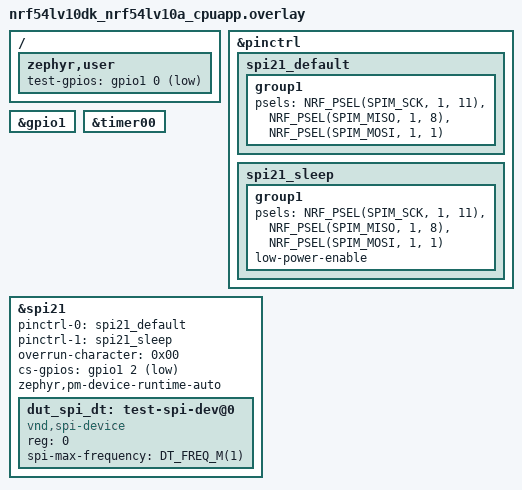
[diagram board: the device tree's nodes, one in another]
/*
 * Copyright (c) 2025 Nordic Semiconductor ASA
 *
 * SPDX-License-Identifier: LicenseRef-Nordic-5-Clause
 */

/* Test requires wire connection:
 *  - SPIM_MOSI with test-gpios -> P1.0 - P1.1.
 */

/ {
	zephyr,user {
		test-gpios = <&gpio1 0 GPIO_ACTIVE_LOW>;
	};
};

&pinctrl {
	spi21_default: spi21_default {
		group1 {
			psels = <NRF_PSEL(SPIM_SCK, 1, 11)>,
				<NRF_PSEL(SPIM_MISO, 1, 8)>,
				<NRF_PSEL(SPIM_MOSI, 1, 1)>;
		};
	};

	spi21_sleep: spi21_sleep {
		group1 {
			psels = <NRF_PSEL(SPIM_SCK, 1, 11)>,
				<NRF_PSEL(SPIM_MISO, 1, 8)>,
				<NRF_PSEL(SPIM_MOSI, 1, 1)>;
			low-power-enable;
		};
	};
};

&gpio1 {
	status = "okay";
};

&timer00 {
	status = "okay";
};

&spi21 {
	status = "okay";
	pinctrl-0 = <&spi21_default>;
	pinctrl-1 = <&spi21_sleep>;
	pinctrl-names = "default", "sleep";
	overrun-character = <0x00>;
	cs-gpios = <&gpio1 2 GPIO_ACTIVE_LOW>;
	zephyr,pm-device-runtime-auto;

	dut_spi_dt: test-spi-dev@0 {
		compatible = "vnd,spi-device";
		reg = <0>;
		spi-max-frequency = <DT_FREQ_M(1)>;
	};
};
